# AT32F415xx register map
Vendor: Keil; Series: AT32F415; File version: 1.0
CPU: CM4 r0p1, little endian, no MPU, FPU, 4 interrupt priority bits
Registers are 32-bit, read-write, reset 0x0 unless marked. A register's access mark holds for its fields unless they carry their own. Offsets are from the block's base; [hi:lo] are bit positions.

## I2C1 — Inter integrated circuit
Base 0x40005400
Same registers: I2C2 0x40005800
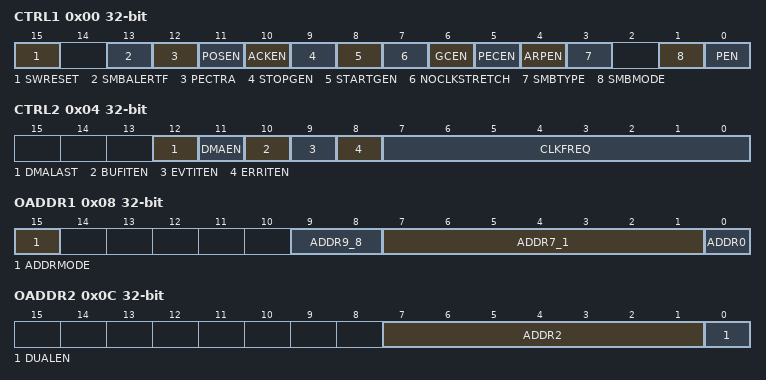
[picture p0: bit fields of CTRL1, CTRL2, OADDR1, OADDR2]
0x00 CTRL1 — Control register 1
  [15] SWRESET — Software reset
  [13] SMBALERTF — SMBus alert
  [12] PECTRA — Packet error checking
  [11] POSEN — Acknowledge/PEC Position (for data reception)
  [10] ACKEN — Acknowledge enable
  [9] STOPGEN — Stop generation
  [8] STARTGEN — Start generation
  [7] NOCLKSTRETCH — Clock stretching disable (Slave mode)
  [6] GCEN — General call enable
  [5] PECEN — PEC enable
  [4] ARPEN — ARP enable
  [3] SMBTYPE — SMBus type
  [1] SMBMODE — SMBus mode
  [0] PEN — Peripheral enable
0x04 CTRL2 — Control register 2
  [12] DMALAST — DMA last transfer
  [11] DMAEN — DMA requests enable
  [10] BUFITEN — Buffer interrupt enable
  [9] EVTITEN — Event interrupt enable
  [8] ERRITEN — Error interrupt enable
  [7:0] CLKFREQ — Peripheral clock frequency
0x08 OADDR1 — Own address register 1
  [15] ADDRMODE — Addressing mode (slave mode)
  [9:8] ADDR9_8 — Interface address bit9 and bit8
  [7:1] ADDR7_1 — Interface address bit7~bit1
  [0] ADDR0 — Interface address bit0
0x0C OADDR2 — Own address register 2
  [7:1] ADDR2 — Interface address
  [0] DUALEN — Dual addressing mode enable
0x10 DT — Data register
  [7:0] DT — 8-bit data register
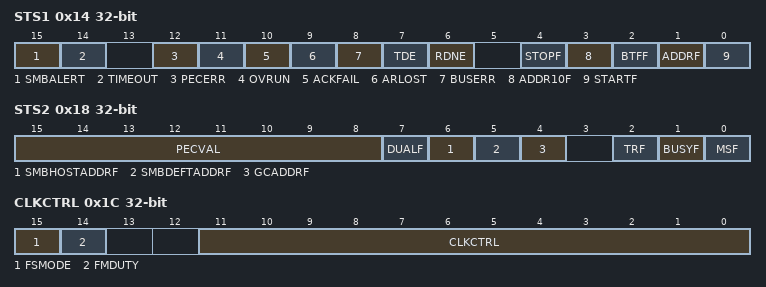
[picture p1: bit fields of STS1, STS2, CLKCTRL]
0x14 STS1 — Status register 1
  [15] SMBALERT — SMBus alert
  [14] TIMEOUT — Timeout or Tlow error
  [12] PECERR — PEC Error in reception
  [11] OVRUN — Overrun/Underrun
  [10] ACKFAIL — Acknowledge failure
  [9] ARLOST — Arbitration lost (master mode)
  [8] BUSERR — Bus error
  [7] TDE ro — Data register empty (transmitters)
  [6] RDNE ro — Data register not empty (receivers)
  [4] STOPF ro — Stop detection (slave mode)
  [3] ADDR10F ro — 10-bit header sent (Master mode)
  [2] BTFF ro — Byte transfer finished
  [1] ADDRF ro — Address sent (master mode)/matched (slave mode)
  [0] STARTF ro — Start bit (Master mode)
0x18 STS2 ro — Status register 2
  [15:8] PECVAL — acket error checking register
  [7] DUALF — Dual flag (Slave mode)
  [6] SMBHOSTADDRF — SMBus host header (Slave mode)
  [5] SMBDEFTADDRF — SMBus device default address (Slave mode)
  [4] GCADDRF — General call address (Slave mode)
  [2] TRF — Transmitter/receiver
  [1] BUSYF — Bus busy
  [0] MSF — Master/slave
0x1C CLKCTRL — Clock control register
  [15] FSMODE — I2C master mode selection
  [14] FMDUTY — Fast mode duty cycle
  [11:0] CLKCTRL — Clock control register in Fast/Standard mode (Master mode)
0x20 TMRISE reset 0x2 — TRISE register
  [5:0] TMRISE — Maximum rise time in Fast/Standard mode (Master mode)

## SPI1 — Serial peripheral interface
Base 0x40013000
Same registers: SPI2 0x40003800
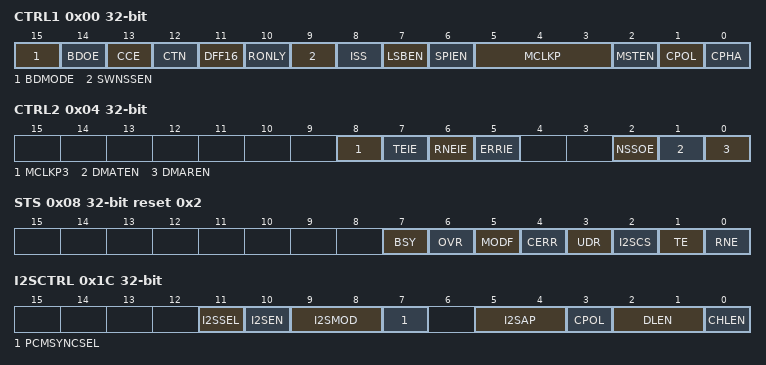
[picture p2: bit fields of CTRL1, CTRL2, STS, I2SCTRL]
0x00 CTRL1 — control register 1
  [15] BDMODE — Bidirectional data mode enable
  [14] BDOE — Output enable in bidirectional mode
  [13] CCE — Hardware CRC calculation enable
  [12] CTN — CRC transfer next
  [11] DFF16 — Data frame format
  [10] RONLY — Receive only
  [9] SWNSSEN — Software slave management
  [8] ISS — Internal slave select
  [7] LSBEN — Frame format
  [6] SPIEN — SPI enable
  [5:3] MCLKP — Baud rate control
  [2] MSTEN — Master selection
  [1] CPOL — Clock polarity
  [0] CPHA — Clock phase
0x04 CTRL2 — control register 2
  [8] MCLKP3 — Baud rate control bit3
  [7] TEIE — Tx buffer empty interrupt enable
  [6] RNEIE — RX buffer not empty interrupt enable
  [5] ERRIE — Error interrupt enable
  [2] NSSOE — SS output enable
  [1] DMATEN — Tx buffer DMA enable
  [0] DMAREN — Rx buffer DMA enable
0x08 STS reset 0x2 — status register
  [7] BSY ro — Busy flag
  [6] OVR ro — Overrun flag
  [5] MODF ro — Mode fault
  [4] CERR — CRC error flag
  [3] UDR ro — Underrun flag
  [2] I2SCS ro — Channel side
  [1] TE ro — Transmit buffer empty
  [0] RNE ro — Receive buffer not empty
0x0C DT — data register
  [15:0] DT — Data register
0x10 CPOLY reset 0x7 — CRC polynomial register
  [15:0] CPOLY
0x14 RCRC ro — RX CRC register
  [15:0] RCRC — Rx CRC register
0x18 TCRC ro — TX CRC register
  [15:0] TCRC — Tx CRC register
0x1C I2SCTRL — I2S configuration register
  [11] I2SSEL — I2S mode selection
  [10] I2SEN — I2S Enable
  [9:8] I2SMOD — I2S configuration mode
  [7] PCMSYNCSEL — PCM frame synchronization
  [5:4] I2SAP — I2S standard selection
  [3] CPOL — Steady state clock polarity
  [2:1] DLEN — Data length to be transferred
  [0] CHLEN — Channel length (number of bits per audio channel)
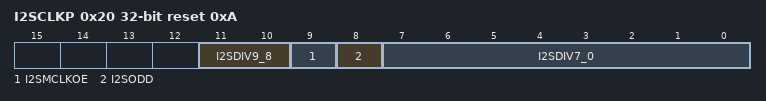
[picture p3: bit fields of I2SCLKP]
0x20 I2SCLKP reset 0xA — I2S prescaler register
  [11:10] I2SDIV9_8 — I2S Linear prescaler bit9 and bit8
  [9] I2SMCLKOE — Master clock output enable
  [8] I2SODD — Odd factor for the prescaler
  [7:0] I2SDIV7_0 — I2S Linear prescaler bit7 to bit0
